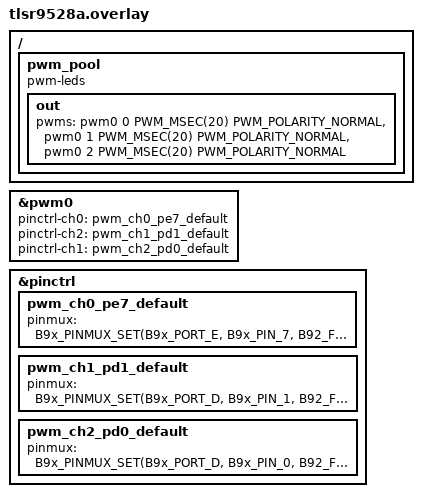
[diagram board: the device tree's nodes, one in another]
/*
 * Copyright (c) 2024 Telink Semiconductor
 *
 * SPDX-License-Identifier: Apache-2.0
 */

/ {
	pwm_pool {
		compatible = "pwm-leds";
		out {
			pwms = <&pwm0 0 PWM_MSEC(20) PWM_POLARITY_NORMAL>,
					<&pwm0 1 PWM_MSEC(20) PWM_POLARITY_NORMAL>,
					<&pwm0 2 PWM_MSEC(20) PWM_POLARITY_NORMAL>;
		};
	};
};

&pwm0 {
	/* On board RGB LEDs */
	pinctrl-ch0 = <&pwm_ch0_pe7_default>;
	pinctrl-ch2 = <&pwm_ch1_pd1_default>;
	pinctrl-ch1 = <&pwm_ch2_pd0_default>;
};

&pinctrl {
	pwm_ch0_pe7_default: pwm_ch0_pe7_default {
		pinmux = <B9x_PINMUX_SET(B9x_PORT_E, B9x_PIN_7, B92_FUNC_PWM0)>;
	};
	pwm_ch1_pd1_default: pwm_ch1_pd1_default {
		pinmux = <B9x_PINMUX_SET(B9x_PORT_D, B9x_PIN_1, B92_FUNC_PWM1)>;
	};
	pwm_ch2_pd0_default: pwm_ch2_pd0_default {
		pinmux = <B9x_PINMUX_SET(B9x_PORT_D, B9x_PIN_0, B92_FUNC_PWM2)>;
	};
};
